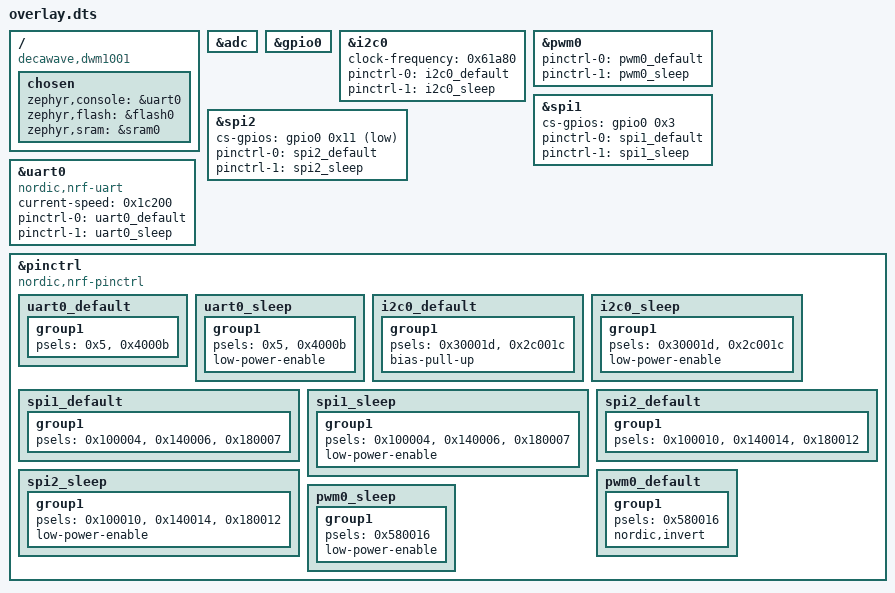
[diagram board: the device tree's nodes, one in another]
/ {
	compatible = "decawave,dwm1001";
	chosen {
		zephyr,console = &uart0;
		zephyr,flash = &flash0;
		zephyr,sram = &sram0;
	};
};
&adc{
	status = "okay";
};
&gpio0{
	status = "okay";
};
&i2c0{
	clock-frequency = < 0x61a80 >;
	status = "okay";
	pinctrl-0 = < &i2c0_default >;
	pinctrl-1 = < &i2c0_sleep >;
	pinctrl-names = "default", "sleep";
};
&pwm0{
	status = "okay";
	pinctrl-0 = < &pwm0_default >;
	pinctrl-1 = < &pwm0_sleep >;
	pinctrl-names = "default", "sleep";
};
&spi1{
	status = "okay";
	cs-gpios = < &gpio0 0x3 0x0 >;
	pinctrl-0 = < &spi1_default >;
	pinctrl-1 = < &spi1_sleep >;
	pinctrl-names = "default", "sleep";
};
&spi2{
	status = "okay";
	cs-gpios = < &gpio0 0x11 0x1 >;
	pinctrl-0 = < &spi2_default >;
	pinctrl-1 = < &spi2_sleep >;
	pinctrl-names = "default", "sleep";
};
&uart0{
	compatible = "nordic,nrf-uart";
	status = "okay";
	current-speed = < 0x1c200 >;
	pinctrl-0 = < &uart0_default >;
	pinctrl-1 = < &uart0_sleep >;
	pinctrl-names = "default", "sleep";
};
&pinctrl{
	compatible = "nordic,nrf-pinctrl";
	uart0_default: uart0_default {
		group1 {
			psels = < 0x5 >, < 0x4000b >;
		};
	};
	uart0_sleep: uart0_sleep {
		group1 {
			psels = < 0x5 >, < 0x4000b >;
			low-power-enable;
		};
	};
	i2c0_default: i2c0_default {
		group1 {
			psels = < 0x30001d >, < 0x2c001c >;
			bias-pull-up;
		};
	};
	i2c0_sleep: i2c0_sleep {
		group1 {
			psels = < 0x30001d >, < 0x2c001c >;
			low-power-enable;
		};
	};
	spi1_default: spi1_default {
		group1 {
			psels = < 0x100004 >, < 0x140006 >, < 0x180007 >;
		};
	};
	spi1_sleep: spi1_sleep {
		group1 {
			psels = < 0x100004 >, < 0x140006 >, < 0x180007 >;
			low-power-enable;
		};
	};
	spi2_default: spi2_default {
		group1 {
			psels = < 0x100010 >, < 0x140014 >, < 0x180012 >;
		};
	};
	spi2_sleep: spi2_sleep {
		group1 {
			psels = < 0x100010 >, < 0x140014 >, < 0x180012 >;
			low-power-enable;
		};
	};
	pwm0_default: pwm0_default {
		group1 {
			psels = < 0x580016 >;
			nordic,invert;
		};
	};
	pwm0_sleep: pwm0_sleep {
		group1 {
			psels = < 0x580016 >;
			low-power-enable;
		};
	};
};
